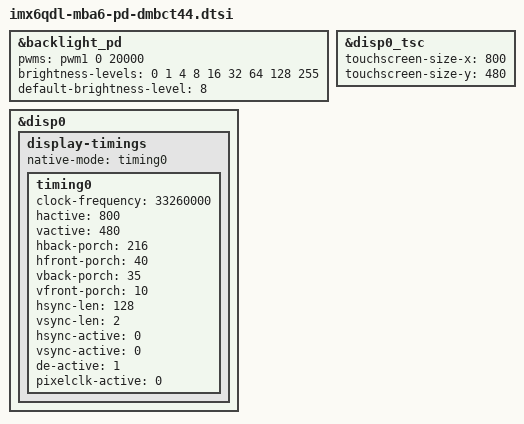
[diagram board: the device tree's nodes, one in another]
/*
 * Copyright 2014 Markus Niebel, TQ Systems GmbH
 *
 * The code contained herein is licensed under the GNU General Public
 * License. You may obtain a copy of the GNU General Public License
 * Version 2 or later at the following locations:
 *
 * http://www.opensource.org/licenses/gpl-license.html
 * http://www.gnu.org/copyleft/gpl.html
 */

#include "imx6qdl-mba6-pd.dtsi"

&backlight_pd {
	pwms = <&pwm1 0 20000>; /* 50 kHz */
	brightness-levels = <0 1 4 8 16 32 64 128 255>;
	default-brightness-level = <8>;
};

&disp0 {
	display-timings {
		/* ET0700G0DH6 + ETM0700G0DH6 + ETM0700G0BDH6 + S070WV106H-CT44 */
		native-mode = <&timing0>;
		timing0: timing0 {
			clock-frequency = <33260000>;
			hactive = <800>;
			vactive = <480>;
			hback-porch = <216>;
			hfront-porch = <40>;
			vback-porch = <35>;
			vfront-porch = <10>;
			hsync-len = <128>;
			vsync-len = <2>;
			hsync-active = <0>;
			vsync-active = <0>;
			de-active = <1>;
			pixelclk-active = <0>;
		};
	};
};

&disp0_tsc {
	touchscreen-size-x = <800>;
	touchscreen-size-y = <480>;
};

